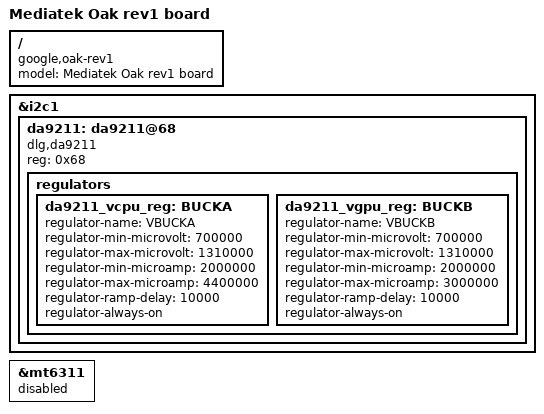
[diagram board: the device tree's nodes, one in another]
/*
 * Copyright (c) 2014 MediaTek Inc.
 * Author: Eddie Huang <eddie.huang@mediatek.com>
 *
 * This program is free software; you can redistribute it and/or modify
 * it under the terms of the GNU General Public License version 2 as
 * published by the Free Software Foundation.
 *
 * This program is distributed in the hope that it will be useful,
 * but WITHOUT ANY WARRANTY; without even the implied warranty of
 * MERCHANTABILITY or FITNESS FOR A PARTICULAR PURPOSE.  See the
 * GNU General Public License for more details.
 */

/dts-v1/;
#include "mt8173-oak.dtsi"

/ {
	model = "Mediatek Oak rev1 board";
	compatible = "google,oak-rev1", "google,oak", "mediatek,mt8173";
};

&i2c1 {
	da9211: da9211@68 {
		compatible = "dlg,da9211";
		reg = <0x68>;

		regulators {
			da9211_vcpu_reg: BUCKA {
				regulator-name = "VBUCKA";
				regulator-min-microvolt = < 700000>;
				regulator-max-microvolt = <1310000>;
				regulator-min-microamp	= <2000000>;
				regulator-max-microamp	= <4400000>;
				regulator-ramp-delay = <10000>;
				regulator-always-on;
			};

			da9211_vgpu_reg: BUCKB {
				regulator-name = "VBUCKB";
				regulator-min-microvolt = < 700000>;
				regulator-max-microvolt = <1310000>;
				regulator-min-microamp	= <2000000>;
				regulator-max-microamp	= <3000000>;
				regulator-ramp-delay = <10000>;
				regulator-always-on;
			};
		};
	};
};

&mt6311 {
	status = "disabled";
};
